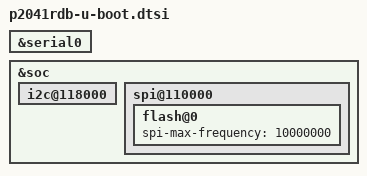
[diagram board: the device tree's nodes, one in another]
// SPDX-License-Identifier: GPL-2.0+

&serial0 {
	bootph-all;
};

&soc {
	i2c@118000 {
		bootph-all;
	};

	spi@110000 {
		flash@0 {
			spi-max-frequency = <10000000>;
		};
	};
};

#include "u-boot.dtsi"
